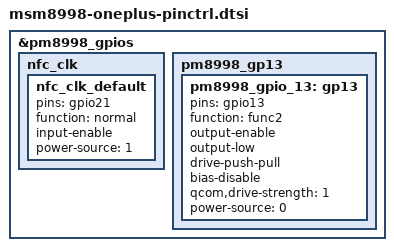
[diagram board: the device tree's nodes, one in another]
/* Copyright (c) 2016-2017, The Linux Foundation. All rights reserved.
 *
 * This program is free software; you can redistribute it and/or modify
 * it under the terms of the GNU General Public License version 2 and
 * only version 2 as published by the Free Software Foundation.
 *
 * This program is distributed in the hope that it will be useful,
 * but WITHOUT ANY WARRANTY; without even the implied warranty of
 * MERCHANTABILITY or FITNESS FOR A PARTICULAR PURPOSE.  See the
 * GNU General Public License for more details.
 */

&pm8998_gpios {
	/* GPIO 21 (NFC_CLK_REQ) */
	nfc_clk {
		nfc_clk_default: nfc_clk_default {
			pins = "gpio21";
			function = "normal";
			input-enable;
			power-source = <1>;
		};
	};

	/* GPIO 13, speaker I2S master clock */
	pm8998_gp13 {
		pm8998_gpio_13: gp13 {
			pins = "gpio13";
			function = "func2";
			output-enable;
			output-low;
			drive-push-pull;
			bias-disable;
			qcom,drive-strength = <1>;
			power-source = <0>;
		};
	};
};
